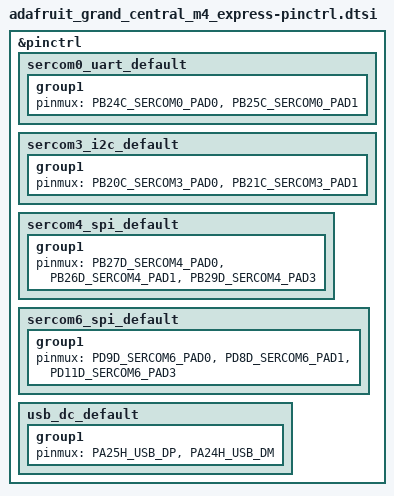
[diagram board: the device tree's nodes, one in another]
/*
 * Copyright (c) 2023 Lukas Jung <lukas.jung@mailbox.org>
 * SPDX-License-Identifier: Apache-2.0
 */

#include <dt-bindings/pinctrl/samd51p-pinctrl.h>

&pinctrl {
	sercom0_uart_default: sercom0_uart_default {
		group1 {
			pinmux = <PB24C_SERCOM0_PAD0>,
				 <PB25C_SERCOM0_PAD1>;
		};
	};

	sercom3_i2c_default: sercom3_i2c_default {
		group1 {
			pinmux = <PB20C_SERCOM3_PAD0>,
				 <PB21C_SERCOM3_PAD1>;
		};
	};

	sercom4_spi_default: sercom4_spi_default {
		group1 {
			pinmux = <PB27D_SERCOM4_PAD0>,
				 <PB26D_SERCOM4_PAD1>,
				 <PB29D_SERCOM4_PAD3>;
		};
	};

	sercom6_spi_default: sercom6_spi_default {
		group1 {
			pinmux = <PD9D_SERCOM6_PAD0>,
				 <PD8D_SERCOM6_PAD1>,
				 <PD11D_SERCOM6_PAD3>;
		};
	};

	usb_dc_default: usb_dc_default {
		group1 {
			pinmux = <PA25H_USB_DP>,
				 <PA24H_USB_DM>;
		};
	};
};
